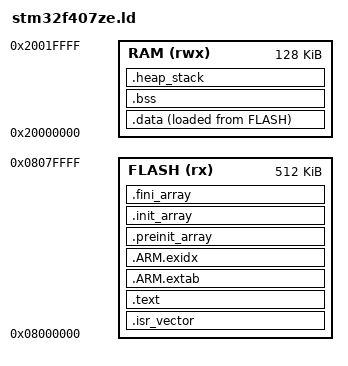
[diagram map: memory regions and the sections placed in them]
/* STM32F407ZET6：512 KiB Flash、128 KiB 普通 SRAM，第一版不使用 CCM。 */
ENTRY(Reset_Handler)
MEMORY {
  FLASH (rx) : ORIGIN = 0x08000000, LENGTH = 512K
  RAM (rwx) : ORIGIN = 0x20000000, LENGTH = 128K
}
_estack = ORIGIN(RAM) + LENGTH(RAM);
SECTIONS {
  .isr_vector : { KEEP(*(.isr_vector)) } > FLASH
  .text : { *(.text*) *(.rodata*) KEEP(*(.init)) KEEP(*(.fini)) } > FLASH
  .ARM.extab : { *(.ARM.extab*) } > FLASH
  .ARM.exidx : { __exidx_start = .; *(.ARM.exidx*) __exidx_end = .; } > FLASH
  .preinit_array : { PROVIDE_HIDDEN(__preinit_array_start = .); KEEP(*(.preinit_array*)) PROVIDE_HIDDEN(__preinit_array_end = .); } > FLASH
  .init_array : { PROVIDE_HIDDEN(__init_array_start = .); KEEP(*(SORT(.init_array.*))) KEEP(*(.init_array*)) PROVIDE_HIDDEN(__init_array_end = .); } > FLASH
  .fini_array : { PROVIDE_HIDDEN(__fini_array_start = .); KEEP(*(SORT(.fini_array.*))) KEEP(*(.fini_array*)) PROVIDE_HIDDEN(__fini_array_end = .); } > FLASH
  _sidata = LOADADDR(.data);
  .data : { . = ALIGN(4); _sdata = .; *(.data*) . = ALIGN(4); _edata = .; } > RAM AT> FLASH
  .bss (NOLOAD) : { . = ALIGN(4); _sbss = .; *(.bss*) *(COMMON) . = ALIGN(4); _ebss = .; } > RAM
  .heap_stack (NOLOAD) : { . = ALIGN(8); end = .; _end = .; _heap_start = .; . += 0x2000; _heap_end = .; . += 0x1000; } > RAM
  /DISCARD/ : { *(.note.GNU-stack) }
}
